# STNRG328A register map
Vendor: STMicroelectronics; Series: STNRG; File version: 1.0
CPU: other r1p0, big endian, no MPU, no FPU, 4 interrupt priority bits
Registers are 8-bit, read-write, reset 0x0 unless marked. A register's access mark holds for its fields unless they carry their own. Offsets are from the block's base; [hi:lo] are bit positions; {n}, {i} and the like mark numbered series; 'fields as' and 'values as' point back to an identical list.

## OPT
Base 0x00004800
0x00 ROP — Read-out protection register
0x01 UCB — User boot code register
0x02 NUCB reset 0xFF — User boot code register (complementary byte)
0x03 GENCFG — General configuration register
0x04 NGENCFG reset 0xFF — General configuration register (complementary byte)
0x05 MISCUOPT reset 0x28 — Misc. configuration register
0x06 NMISCUOPT reset 0xD7 — Misc. configuration register (complementary byte)
0x07 CLKCTL reset 0x89 — CKC configuration register
0x08 NCLKCTL reset 0x76 — CKC configuration register (complementary byte)
0x09 HSESTAB — HSE clock stabilization register
0x0A NHSESTAB reset 0xFF — HSE clock stabilization register (complementary byte)
0x0B ENHFEAT — EXP features configuration register
0x0C NENHFEAT reset 0xFF — EXP features configuration register (complementary byte)
0x0D WAITSTATE — Flash wait state register
0x0E NWAITSTATE reset 0xFF — Flash wait state register (complementary byte)
0x0F AFR_IOMXP0 — Alternative Port 0 configuration register
0x10 NAFR_IOMXP0 reset 0xFF — Alternative Port 0 configuration register (complementary byte)
0x11 AFR_IOMXP1 reset 0x1F — Alternative Port 1 configuration register
0x12 NAFR_IOMXP1 reset 0xE0 — Alternative Port 1 configuration register (complementary byte)
0x13 AFR_IOMXP2 reset 0x7A — Alternative Port 2 configuration register
0x14 NAFR_IOMXP2 reset 0x85 — Alternative Port 2 configuration register (complementary byte)
0x15 MSC_OPT0 reset 0x1 — Misc. configuration register 0
0x16 NMSC_OPT0 reset 0xFE — Misc. configuration register 0 (complementary byte)
0x7E OPTBL — Bootloader register
0x7F NOPTBL reset 0xFF — Bootloader register (complementary byte)

## PORT0
Base 0x00005000
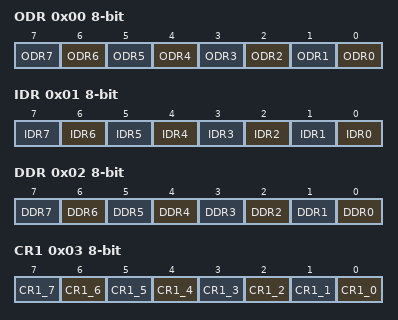
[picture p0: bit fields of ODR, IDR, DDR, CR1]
0x00 ODR — Port 0 output register
  [n] ODR{n} (n=0..7)
0x01 IDR — Port 0 input register
  [n] IDR{n} (n=0..7)
0x02 DDR — Port 0 data direction register
  [n] DDR{n} (n=0..7)
0x03 CR1 — Port 0 control register 1
  [n] CR1_{n} (n=0..7)
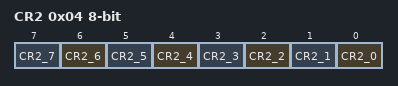
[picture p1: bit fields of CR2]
0x04 CR2 — Port 0 control register 2
  [n] CR2_{n} (n=0..7)

## PORT1
Base 0x00005005
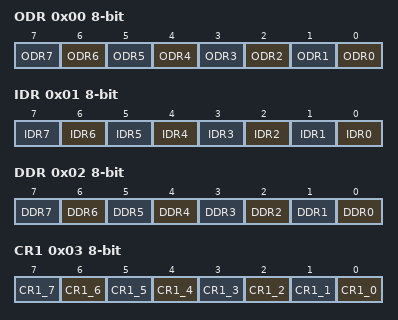
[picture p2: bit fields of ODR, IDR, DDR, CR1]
0x00 ODR — Port 1 output register
  [n] ODR{n} (n=0..7)
0x01 IDR — Port 1 input register
  [n] IDR{n} (n=0..7)
0x02 DDR — Port 1 data direction register
  [n] DDR{n} (n=0..7)
0x03 CR1 — Port 1 control register 1
  [n] CR1_{n} (n=0..7)
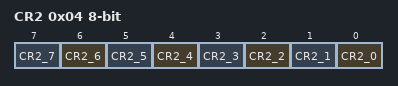
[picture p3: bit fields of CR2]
0x04 CR2 — Port 1 control register 2
  [n] CR2_{n} (n=0..7)

## RST
Base 0x000050B3
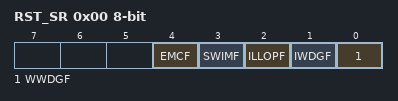
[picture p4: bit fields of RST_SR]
0x00 RST_SR — Reset status register
  [4] EMCF, [3] SWIMF, [2] ILLOPF, [1] IWDGF, [0] WWDGF

## SMED0
Base 0x00005500
Same registers: SMED1 0x00005540, SMED2 0x00005580, SMED3 0x000055C0, SMED4 0x00005600, SMED5 0x00005640
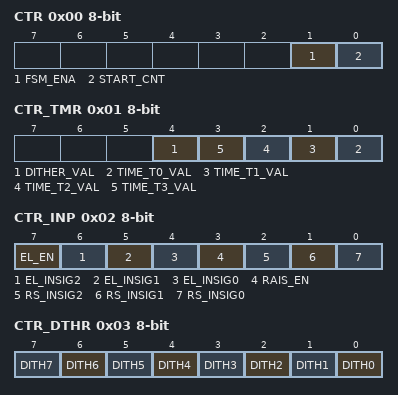
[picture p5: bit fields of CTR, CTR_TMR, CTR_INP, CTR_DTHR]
0x00 CTR — Control register
  [1] FSM_ENA, [0] START_CNT
0x01 CTR_TMR — Control timer register
  [4] DITHER_VAL, [n] TIME_T{n}_VAL (n=0..3)
0x02 CTR_INP — Control input register
  [7] EL_EN, [6] EL_INSIG2, [5] EL_INSIG1, [4] EL_INSIG0, [3] RAIS_EN, [2] RS_INSIG2, [1] RS_INSIG1, [0] RS_INSIG0
0x03 CTR_DTHR — Dithering register
  [n] DITH{n} (n=0..7)
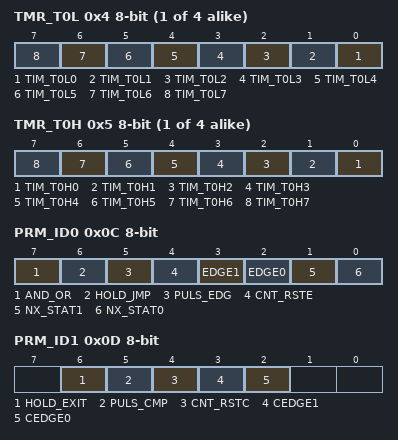
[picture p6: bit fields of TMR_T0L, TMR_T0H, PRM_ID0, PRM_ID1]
{0x4+2i} TMR_T{i}L (i=0..3) — Time T{i} lsb register
  [n] TIM_T{i}L{n} (n=0..7)
{0x5+2i} TMR_T{i}H (i=0..3) — Time T{i} msb register
  [n] TIM_T{i}H{n} (n=0..7)
0x0C PRM_ID0 — Parameter 0 IDLE register
  [7] AND_OR, [6] HOLD_JMP, [5] PULS_EDG, [4] CNT_RSTE, [3] EDGE1, [2] EDGE0, [1] NX_STAT1, [0] NX_STAT0
0x0D PRM_ID1 — Parameter 1 IDLE register
  [6] HOLD_EXIT, [5] PULS_CMP, [4] CNT_RSTC, [3] CEDGE1, [2] CEDGE0
0x0E PRM_ID2 — Parameter 2 IDLE register
  [0] LATCH_RS
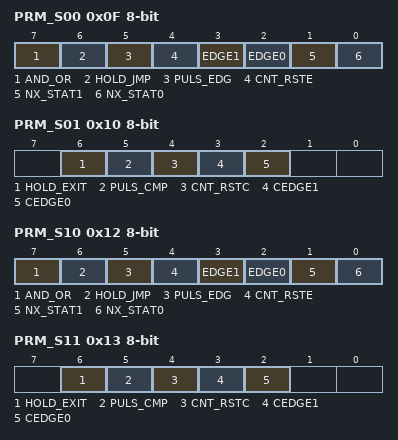
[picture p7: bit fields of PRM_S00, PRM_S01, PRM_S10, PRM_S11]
0x0F PRM_S00 — Parameter 0 S0 register
  fields as PRM_ID0
0x10 PRM_S01 — Parameter 1 S0 register
  [6] HOLD_EXIT, [5] PULS_CMP, [4] CNT_RSTC, [3] CEDGE1, [2] CEDGE0
0x11 PRM_S02 — Parameter 2 S0 register
  [0] LATCH_RS
0x12 PRM_S10 — Parameter 0 S1 register
  fields as PRM_ID0
0x13 PRM_S11 — Parameter 1 S1 register
  [6] HOLD_EXIT, [5] PULS_CMP, [4] CNT_RSTC, [3] CEDGE1, [2] CEDGE0
0x14 PRM_S12 — Parameter 2 S1 register
  [0] LATCH_RS
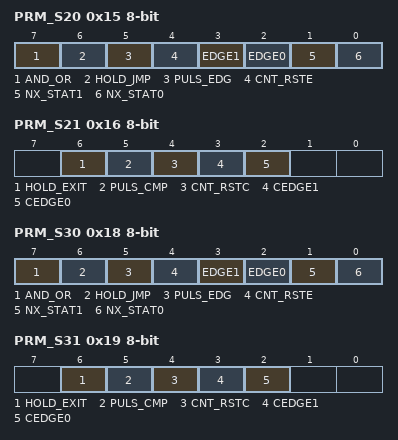
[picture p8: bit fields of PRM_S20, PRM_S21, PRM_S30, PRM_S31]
0x15 PRM_S20 — Parameter 0 S2 register
  fields as PRM_ID0
0x16 PRM_S21 — Parameter 1 S2 register
  [6] HOLD_EXIT, [5] PULS_CMP, [4] CNT_RSTC, [3] CEDGE1, [2] CEDGE0
0x17 PRM_S22 — Parameter 2 S2 register
  [0] LATCH_RS
0x18 PRM_S30 — Parameter 0 S3 register
  fields as PRM_ID0
0x19 PRM_S31 — Parameter 1 S3 register
  [6] HOLD_EXIT, [5] PULS_CMP, [4] CNT_RSTC, [3] CEDGE1, [2] CEDGE0
0x1A PRM_S32 — Parameter 2 S3 register
  [0] LATCH_RS
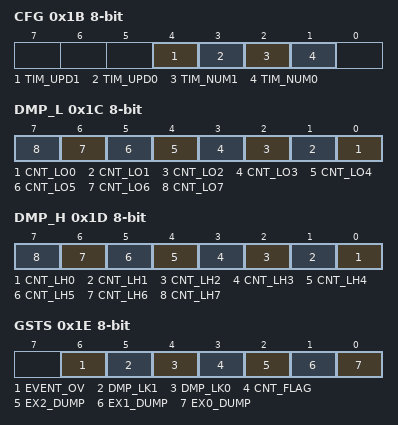
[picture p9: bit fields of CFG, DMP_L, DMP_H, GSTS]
0x1B CFG — Timer configuration register
  [4] TIM_UPD1, [3] TIM_UPD0, [2] TIM_NUM1, [1] TIM_NUM0
0x1C DMP_L — Dump counter lsb register
  [n] CNT_LO{n} (n=0..7)
0x1D DMP_H — Dump counter msb register
  [n] CNT_LH{n} (n=0..7)
0x1E GSTS — General status register
  [6] EVENT_OV, [5] DMP_LK1, [4] DMP_LK0, [3] CNT_FLAG, [2] EX2_DUMP, [1] EX1_DUMP, [0] EX0_DUMP
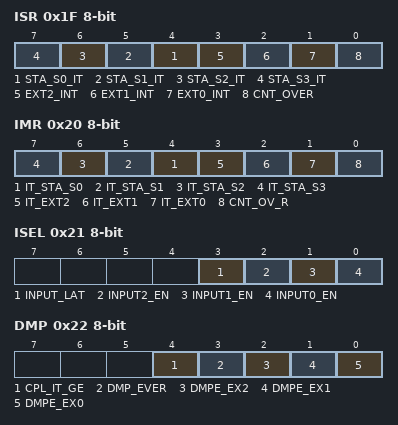
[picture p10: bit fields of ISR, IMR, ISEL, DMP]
0x1F ISR — Interrupt status register
  [n+4] STA_S{n}_IT (n=0..3), [3] EXT2_INT, [2] EXT1_INT, [1] EXT0_INT, [0] CNT_OVER
0x20 IMR — Interrupt mask register
  [n+4] IT_STA_S{n} (n=0..3), [3] IT_EXT2, [2] IT_EXT1, [1] IT_EXT0, [0] CNT_OV_R
0x21 ISEL — External event control register
  [3] INPUT_LAT, [2] INPUT2_EN, [1] INPUT1_EN, [0] INPUT0_EN
0x22 DMP — Dump enable register
  [4] CPL_IT_GE, [3] DMP_EVER, [2] DMPE_EX2, [1] DMPE_EX1, [0] DMPE_EX0
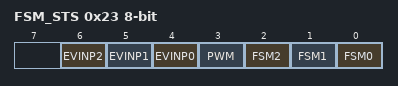
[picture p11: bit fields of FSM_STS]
0x23 FSM_STS — FSM status register
  [6] EVINP2, [5] EVINP1, [4] EVINP0, [3] PWM, [2] FSM2, [1] FSM1, [0] FSM0

## STMR
Base 0x00005340
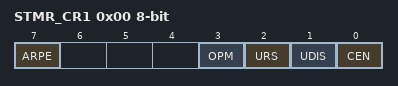
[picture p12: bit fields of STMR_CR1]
0x00 STMR_CR1 — Control register 1
  [7] ARPE, [3] OPM, [2] URS, [1] UDIS, [0] CEN
0x01 STMR_IER — Interrupt enable register
  [0] UIE
0x02 STMR_SR1 — Status register
  [0] UIF
0x03 STMR_EGR — Event generation register
  [0] UG
0x04 STMR_CNTH — Counter high register
  [7:0] CNT
0x05 STMR_CNTL — Counter low register
  [7:0] CNT
0x06 STMR_PSCL — Prescaler register
  [2:0] PSC
0x07 STMR_ARRH reset 0xFF — Auto-reload high register
  [7:0] ARR
0x08 STMR_ARRL reset 0xFF — Auto-reload low register
  [7:0] ARR

## SYS
Base 0x00007F60
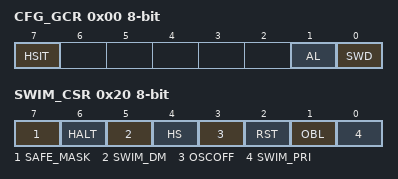
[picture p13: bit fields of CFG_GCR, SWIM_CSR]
0x00 CFG_GCR — Global configuration register
  [7] HSIT, [1] AL, [0] SWD
0x20 SWIM_CSR — SWIM control status register
  [7] SAFE_MASK, [6] HALT, [5] SWIM_DM, [4] HS, [3] OSCOFF, [2] RST, [1] OBL, [0] SWIM_PRI

## UART
Base 0x00005230
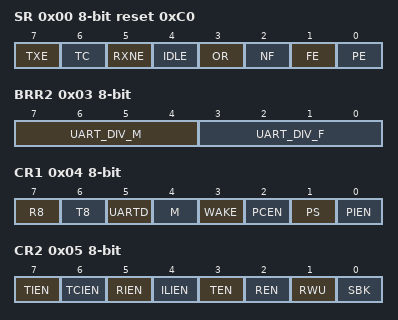
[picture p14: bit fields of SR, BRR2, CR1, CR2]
0x00 SR reset 0xC0 — UART status register
  [7] TXE, [6] TC, [5] RXNE, [4] IDLE, [3] OR, [2] NF, [1] FE, [0] PE
0x01 DR — UART data register
0x02 BRR1 — UART baud rate register 1
  [7:0] UART_DIV_L
0x03 BRR2 — UART baud rate register 2
  [7:4] UART_DIV_M, [3:0] UART_DIV_F
0x04 CR1 — UART control register 1
  [7] R8, [6] T8, [5] UARTD, [4] M, [3] WAKE, [2] PCEN, [1] PS, [0] PIEN
0x05 CR2 — UART control register 2
  [7] TIEN, [6] TCIEN, [5] RIEN, [4] ILIEN, [3] TEN, [2] REN, [1] RWU, [0] SBK
0x06 CR3 — UART control register 3
  [5:4] STOP
0x07 CR4 — UART control register 4
  [3:0] ADD
0x09 GTR — UART guard time register
  [7:0] GT
0x0A PSCR — UART prescaler register
  [7:0] PSC

## WDG
Base 0x000050D1
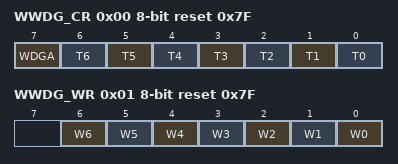
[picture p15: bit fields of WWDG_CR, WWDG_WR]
0x00 WWDG_CR reset 0x7F — WWDG control register
  [7] WDGA, [n] T{n} (n=0..6)
0x01 WWDG_WR reset 0x7F — WWDR window register
  [n] W{n} (n=0..6)
0x0F IWDG_KR — IWDG key register
  [7:0] KEY
0x10 IWDG_PR — IWDG prescaler register
  [2:0] PR
0x11 IWDG_RLR reset 0xFF — IWDG reload register
  [7:0] RL
